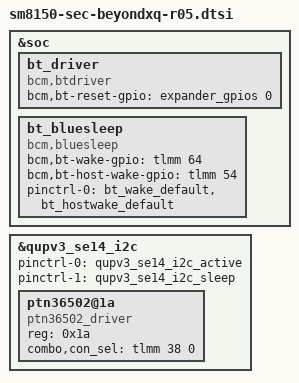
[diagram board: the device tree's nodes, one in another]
/* Copyright (c) 2016-2017, The Linux Foundation. All rights reserved.
 *
 * This program is free software; you can redistribute it and/or modify
 * it under the terms of the GNU General Public License version 2 and
 * only version 2 as published by the Free Software Foundation.
 *
 * This program is distributed in the hope that it will be useful,
 * but WITHOUT ANY WARRANTY; without even the implied warranty of
 * MERCHANTABILITY or FITNESS FOR A PARTICULAR PURPOSE.  See the
 * GNU General Public License for more details.
 */

#include "sm8150-sec-beyondxq-common.dtsi"
#include "sm8150-sec-beyondxq-optics-r00.dtsi"

&soc {
	bt_driver {
		compatible = "bcm,btdriver";  //bt_en
		pinctrl-names = "default";
		bcm,bt-reset-gpio = <&expander_gpios 0 GPIO_ACTIVE_HIGH>;
		status = "okay";
	};

	bt_bluesleep {
		compatible = "bcm,bluesleep";
		bcm,bt-wake-gpio = <&tlmm 64 0>;
		bcm,bt-host-wake-gpio = <&tlmm 54 0>;
		pinctrl-names = "default";
		pinctrl-0 = <&bt_wake_default &bt_hostwake_default>;
		status = "okay";
	};
};

&qupv3_se14_i2c {
	status = "ok";

	pinctrl-names = "default", "sleep";
	pinctrl-0 = <&qupv3_se14_i2c_active>;
	pinctrl-1 = <&qupv3_se14_i2c_sleep>;

	ptn36502@1a {
		compatible = "ptn36502_driver";
		reg = <0x1a>;
		combo,con_sel = <&tlmm 38 0>;
	};
};
